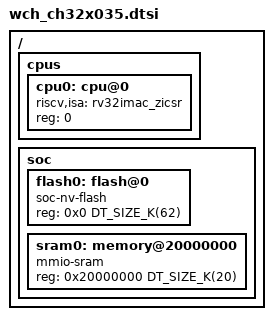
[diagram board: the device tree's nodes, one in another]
/dts-v1/;

#include <mem.h>

/ {
    cpus {
        #address-cells = <1>;
		#size-cells = <0>;

        cpu0: cpu@0 {
            device_type = "cpu";
			riscv,isa = "rv32imac_zicsr";
			reg = <0>;
        };
    };

    soc {
        #address-cells = <1>;
		#size-cells = <1>;

        flash0: flash@0 {
            compatible = "soc-nv-flash";
            reg = <0x0 DT_SIZE_K(62)>;
        };

        sram0: memory@20000000 {
            compatible = "mmio-sram";
            reg = <0x20000000 DT_SIZE_K(20)>;
        };
    };

    // TODO support variants
};
